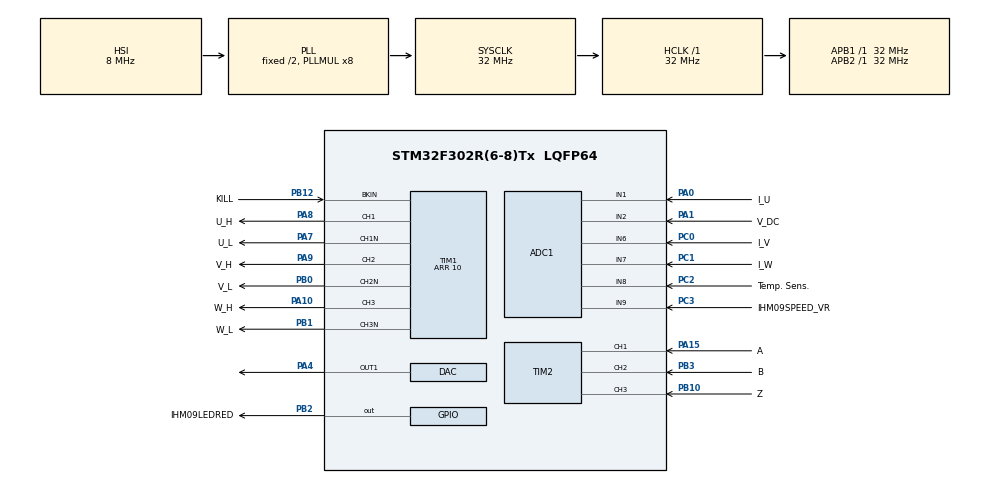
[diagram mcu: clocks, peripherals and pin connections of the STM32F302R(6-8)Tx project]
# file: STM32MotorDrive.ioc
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ADC1.Channel-4\#ChannelRegularConversion=ADC_CHANNEL_1
ADC1.NbrOfConversionFlag=1
ADC1.Offset-4\#ChannelRegularConversion=0
ADC1.OffsetNumber-4\#ChannelRegularConversion=ADC_OFFSET_NONE
ADC1.Rank-4\#ChannelRegularConversion=1
ADC1.SamplingTime-4\#ChannelRegularConversion=ADC_SAMPLETIME_1CYCLE_5
ADC1.SubFamily=STM32F302x8
ADC1.master=1
DAC.DAC_Trigger=DAC_TRIGGER_SOFTWARE
Mcu.Family=STM32F3
Mcu.Name=STM32F302R(6-8)Tx
Mcu.Package=LQFP64
NVIC.PriorityGroup=NVIC_PRIORITYGROUP_4
NVIC.TIM6_DAC_IRQn=true\:0\:0\:false\:false\:true\:true\:true
PA0.GPIO_Label=I_U
PA0.Mode=IN1-Single-Ended
PA0.Signal=ADC1_IN1
PA1.GPIO_Label=V_DC
PA1.Mode=IN2-Single-Ended
PA1.Signal=ADC1_IN2
PA10.GPIO_Label=W_H
PA10.Signal=S_TIM1_CH3
PA15.GPIO_Label=A
PA15.GPIO_PuPd=GPIO_PULLUP
PA15.Signal=S_TIM2_CH1_ETR
PA4.Signal=COMP_DAC1_group
PA7.GPIO_Label=U_L
PA7.Mode=Output Compare1 CH1 CH1N
PA7.Signal=TIM1_CH1N
PA8.GPIO_Label=U_H
PA8.Signal=S_TIM1_CH1
PA9.GPIO_Label=V_H
PA9.Signal=S_TIM1_CH2
PB0.GPIO_Label=V_L
PB0.Mode=Output Compare2 CH2 CH2N
PB0.Signal=TIM1_CH2N
PB1.GPIO_Label=W_L
PB1.Mode=Output Compare3 CH3 CH3N
PB1.Signal=TIM1_CH3N
PB10.GPIO_Label=Z
PB10.GPIO_PuPd=GPIO_PULLUP
PB10.Signal=S_TIM2_CH3
PB12.GPIO_Label=KILL
PB12.Mode=Activate-Break-Input
PB12.Signal=TIM1_BKIN
PB2.GPIO_Label=IHM09LEDRED
PB2.GPIO_PuPd=GPIO_NOPULL
PB2.PinState=GPIO_PIN_SET
PB2.Signal=GPIO_Output
PB3.GPIO_Label=B
PB3.GPIO_PuPd=GPIO_PULLUP
PB3.Signal=S_TIM2_CH2
PC0.GPIO_Label=I_V
PC0.Signal=ADCx_IN6
PC1.GPIO_Label=I_W
PC1.Signal=ADCx_IN7
PC2.GPIO_Label=Temp. Sens.
PC2.Signal=ADCx_IN8
PC3.GPIO_Label=IHM09SPEED_VR
PC3.Signal=ADCx_IN9
ProjectManager.HeapSize=0x200
ProjectManager.StackSize=0x400
ProjectManager.TargetToolchain=STM32CubeIDE
RCC.AHBFreq_Value=32000000
RCC.APB1Freq_Value=32000000
RCC.APB1TimFreq_Value=32000000
RCC.APB2Freq_Value=32000000
RCC.APB2TimFreq_Value=32000000
RCC.CortexFreq_Value=32000000
RCC.HCLKFreq_Value=32000000
RCC.HSE_VALUE=8000000
RCC.HSI_VALUE=8000000
RCC.LSE_VALUE=32768
RCC.PLLMUL=RCC_PLL_MUL8
RCC.SYSCLKFreq_VALUE=32000000
RCC.SYSCLKSourceVirtual=RCC_SYSCLKSOURCE_PLLCLK
RCC.USBFreq_Value=32000000
SH.ADCx_IN6.0=ADC1_IN6,IN6-Single-Ended
SH.ADCx_IN7.0=ADC1_IN7,IN7-Single-Ended
SH.ADCx_IN8.0=ADC1_IN8,IN8-Single-Ended
SH.ADCx_IN9.0=ADC1_IN9,IN9-Single-Ended
SH.COMP_DAC1_group.0=DAC_OUT1,DAC_OUT1
SH.S_TIM1_CH1.0=TIM1_CH1,Output Compare1 CH1 CH1N
SH.S_TIM1_CH2.0=TIM1_CH2,Output Compare2 CH2 CH2N
SH.S_TIM1_CH3.0=TIM1_CH3,Output Compare3 CH3 CH3N
SH.S_TIM2_CH1_ETR.0=TIM2_CH1,Encoder_Interface
SH.S_TIM2_CH2.0=TIM2_CH2,Encoder_Interface
SH.S_TIM2_CH3.0=TIM2_CH3,Input_Capture3_from_TI3
TIM1.AutomaticOutput=TIM_AUTOMATICOUTPUT_ENABLE
TIM1.Channel-Output\ Compare1\ CH1\ CH1N=TIM_CHANNEL_1
TIM1.Channel-Output\ Compare2\ CH2\ CH2N=TIM_CHANNEL_2
TIM1.Channel-Output\ Compare3\ CH3\ CH3N=TIM_CHANNEL_3
TIM1.ClockDivision=TIM_CLOCKDIVISION_DIV4
TIM1.CounterMode=TIM_COUNTERMODE_CENTERALIGNED1
TIM1.DeadTime=3
TIM1.Period=10
TIM2.Channel-Input_Capture3_from_TI3=TIM_CHANNEL_3
TIM6.AutoReloadPreload=TIM_AUTORELOAD_PRELOAD_DISABLE
TIM6.Period=50000
TIM6.Prescaler=5000
TIM6.TIM_MasterOutputTrigger=TIM_TRGO_ENABLE
VP_TIM1_VS_ClockSourceINT.Mode=Internal
VP_TIM6_VS_ClockSourceINT.Mode=Enable_Timer
board=custom

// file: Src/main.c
/* USER CODE BEGIN Header */
/**
  ******************************************************************************
  * @file           : main.c
  * @brief          : Main program body
  ******************************************************************************
  * @attention
  *
  * <h2><center>&copy; Copyright (c) 2019 STMicroelectronics.
  * All rights reserved.</center></h2>
  *
  * This software component is licensed by ST under BSD 3-Clause license,
  * the "License"; You may not use this file except in compliance with the
  * License. You may obtain a copy of the License at:
  *                        opensource.org/licenses/BSD-3-Clause
  *
  ******************************************************************************
  */
/* USER CODE END Header */

#include "main.h"
#include "adc.h"
#include "dac.h"
#include "tim.h"
#include "gpio.h"

/* USER CODE BEGIN Includes */
#define  ARM_MATH_CM4
#include "arm_math.h"
/* USER CODE END Includes */

void SystemClock_Config(void);

int main(void)
{

  /* MCU Configuration--------------------------------------------------------*/

  /* Reset of all peripherals, Initializes the Flash interface and the Systick. */
  HAL_Init();

  /* Configure the system clock */
  SystemClock_Config();

  /* Initialize all configured peripherals */
  MX_GPIO_Init();
  MX_ADC1_Init();
  MX_DAC_Init();
  MX_TIM1_Init();
  MX_TIM2_Init();
  MX_TIM6_Init();
  /* USER CODE BEGIN 2 */

  //math.hの動作確認用の適当な平方根計算
  float32_t sqrt_in = 1.0;
  float32_t sqrt_out;
  arm_sqrt_f32(sqrt_in, &sqrt_out);

  /* USER CODE END 2 */

  /* Infinite loop */
  while (1)
  {

  }
}

void SystemClock_Config(void)
{
  RCC_OscInitTypeDef RCC_OscInitStruct = {0};
  RCC_ClkInitTypeDef RCC_ClkInitStruct = {0};
  RCC_PeriphCLKInitTypeDef PeriphClkInit = {0};

  /** Initializes the CPU, AHB and APB busses clocks
  */
  RCC_OscInitStruct.OscillatorType = RCC_OSCILLATORTYPE_HSI;
  RCC_OscInitStruct.HSIState = RCC_HSI_ON;
  RCC_OscInitStruct.HSICalibrationValue = RCC_HSICALIBRATION_DEFAULT;
  RCC_OscInitStruct.PLL.PLLState = RCC_PLL_ON;
  RCC_OscInitStruct.PLL.PLLSource = RCC_PLLSOURCE_HSI;
  RCC_OscInitStruct.PLL.PLLMUL = RCC_PLL_MUL8;
  if (HAL_RCC_OscConfig(&RCC_OscInitStruct) != HAL_OK)
  {
    Error_Handler();
  }
  /** Initializes the CPU, AHB and APB busses clocks
  */
  RCC_ClkInitStruct.ClockType = RCC_CLOCKTYPE_HCLK|RCC_CLOCKTYPE_SYSCLK
                              |RCC_CLOCKTYPE_PCLK1|RCC_CLOCKTYPE_PCLK2;
  RCC_ClkInitStruct.SYSCLKSource = RCC_SYSCLKSOURCE_PLLCLK;
  RCC_ClkInitStruct.AHBCLKDivider = RCC_SYSCLK_DIV1;
  RCC_ClkInitStruct.APB1CLKDivider = RCC_HCLK_DIV1;
  RCC_ClkInitStruct.APB2CLKDivider = RCC_HCLK_DIV1;

  if (HAL_RCC_ClockConfig(&RCC_ClkInitStruct, FLASH_LATENCY_1) != HAL_OK)
  {
    Error_Handler();
  }
  PeriphClkInit.PeriphClockSelection = RCC_PERIPHCLK_TIM1|RCC_PERIPHCLK_ADC1;
  PeriphClkInit.Tim1ClockSelection = RCC_TIM1CLK_HCLK;
  PeriphClkInit.Adc1ClockSelection = RCC_ADC1PLLCLK_DIV1;

  if (HAL_RCCEx_PeriphCLKConfig(&PeriphClkInit) != HAL_OK)
  {
    Error_Handler();
  }
}

void Error_Handler(void)
{
}

/************************ (C) COPYRIGHT STMicroelectronics *****END OF FILE****/
